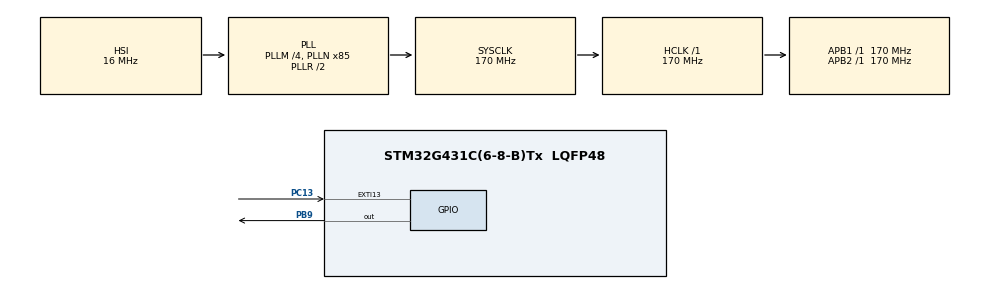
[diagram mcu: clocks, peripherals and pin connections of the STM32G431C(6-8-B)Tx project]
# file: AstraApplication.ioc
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Mcu.Family=STM32G4
Mcu.Name=STM32G431C(6-8-B)Tx
Mcu.Package=LQFP48
NVIC.EXTI15_10_IRQn=true\:0\:0\:false\:false\:true\:true\:true\:true
NVIC.PriorityGroup=NVIC_PRIORITYGROUP_4
PB9.Signal=GPIO_Output
PC13.GPIO_ModeDefaultEXTI=GPIO_MODE_IT_RISING
PC13.GPIO_PuPd=GPIO_PULLDOWN
PC13.Signal=GPXTI13
PC14-OSC32_IN.Mode=LSE-External-Oscillator
PC14-OSC32_IN.Signal=RCC_OSC32_IN
PC15-OSC32_OUT.Mode=LSE-External-Oscillator
PC15-OSC32_OUT.Signal=RCC_OSC32_OUT
PF0-OSC_IN.Mode=HSE-External-Oscillator
PF0-OSC_IN.Signal=RCC_OSC_IN
PF1-OSC_OUT.Mode=HSE-External-Oscillator
PF1-OSC_OUT.Signal=RCC_OSC_OUT
ProjectManager.HeapSize=0x200
ProjectManager.StackSize=0x400
ProjectManager.TargetToolchain=CMake
RCC.ADC12Freq_Value=170000000
RCC.AHBFreq_Value=170000000
RCC.APB1Freq_Value=170000000
RCC.APB1TimFreq_Value=170000000
RCC.APB2Freq_Value=170000000
RCC.APB2TimFreq_Value=170000000
RCC.CortexFreq_Value=170000000
RCC.EXTERNAL_CLOCK_VALUE=12288000
RCC.HCLKFreq_Value=170000000
RCC.HSE_VALUE=8000000
RCC.HSI48_VALUE=48000000
RCC.HSI_VALUE=16000000
RCC.PLLM=RCC_PLLM_DIV4
RCC.PLLN=85
RCC.SYSCLKFreq_VALUE=170000000
RCC.SYSCLKSource=RCC_SYSCLKSOURCE_PLLCLK
RCC.USBFreq_Value=170000000
RCC.VCOOutputFreq_Value=340000000
VP_SYS_VS_DBSignals.Mode=DisableDeadBatterySignals
board=custom

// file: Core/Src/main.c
/* USER CODE BEGIN Header */
/**
  ******************************************************************************
  * @file           : main.c
  * @brief          : Main program body
  ******************************************************************************
  * @attention
  *
  * Copyright (c) 2026 STMicroelectronics.
  * All rights reserved.
  *
  * This software is licensed under terms that can be found in the LICENSE file
  * in the root directory of this software component.
  * If no LICENSE file comes with this software, it is provided AS-IS.
  *
  ******************************************************************************
  */
/* USER CODE END Header */
#include "main.h"

/* USER CODE BEGIN Includes */
#include "FlashLayout.h"
#include "AppHeader.h"
#include "AstraFlash.h"
/* USER CODE END Includes */

/* USER CODE BEGIN PM */

uint32_t flash_buffer[PAGE_SIZE_WORDS];

void EnableOtaRequest(void)
{
    HAL_FLASH_Unlock();

    FlashReadPage(APP_HEADER_ADDR, flash_buffer);

    ((AppHeader_t *)flash_buffer)->otaRequest = OTA_REQUESTED;

    FlashErasePage(APP_HEADER_ADDR);

    FlashWritePage(APP_HEADER_ADDR, flash_buffer);

    HAL_FLASH_Lock();

    NVIC_SystemReset();
}
/* USER CODE END PM */

void SystemClock_Config(void);
static void MX_GPIO_Init(void);

int main(void)
{

  /* USER CODE BEGIN 1 */
  (void)GetAppHeader();
  /* USER CODE END 1 */

  /* MCU Configuration--------------------------------------------------------*/

  /* Reset of all peripherals, Initializes the Flash interface and the Systick. */
  HAL_Init();

  /* USER CODE BEGIN Init */
  SCB->VTOR = APP_START_ADDR;
	__enable_irq();
  /* USER CODE END Init */

  /* Configure the system clock */
  SystemClock_Config();

  /* Initialize all configured peripherals */
  MX_GPIO_Init();
  /* USER CODE BEGIN 2 */
  for (uint32_t blink = 0U; blink <= 3U; blink++)
  {
      HAL_GPIO_TogglePin(GPIOB, GPIO_PIN_9);
      HAL_Delay(500);
  }
  /* USER CODE END 2 */

  /* Infinite loop */
  while (1)
  {

  }
}

void SystemClock_Config(void)
{
  RCC_OscInitTypeDef RCC_OscInitStruct = {0};
  RCC_ClkInitTypeDef RCC_ClkInitStruct = {0};

  /** Configure the main internal regulator output voltage
  */
  HAL_PWREx_ControlVoltageScaling(PWR_REGULATOR_VOLTAGE_SCALE1_BOOST);

  /** Initializes the RCC Oscillators according to the specified parameters
  * in the RCC_OscInitTypeDef structure.
  */
  RCC_OscInitStruct.OscillatorType = RCC_OSCILLATORTYPE_HSI;
  RCC_OscInitStruct.HSIState = RCC_HSI_ON;
  RCC_OscInitStruct.HSICalibrationValue = RCC_HSICALIBRATION_DEFAULT;
  RCC_OscInitStruct.PLL.PLLState = RCC_PLL_ON;
  RCC_OscInitStruct.PLL.PLLSource = RCC_PLLSOURCE_HSI;
  RCC_OscInitStruct.PLL.PLLM = RCC_PLLM_DIV4;
  RCC_OscInitStruct.PLL.PLLN = 85;
  RCC_OscInitStruct.PLL.PLLP = RCC_PLLP_DIV2;
  RCC_OscInitStruct.PLL.PLLQ = RCC_PLLQ_DIV2;
  RCC_OscInitStruct.PLL.PLLR = RCC_PLLR_DIV2;
  if (HAL_RCC_OscConfig(&RCC_OscInitStruct) != HAL_OK)
  {
    Error_Handler();
  }

  /** Initializes the CPU, AHB and APB buses clocks
  */
  RCC_ClkInitStruct.ClockType = RCC_CLOCKTYPE_HCLK|RCC_CLOCKTYPE_SYSCLK
                              |RCC_CLOCKTYPE_PCLK1|RCC_CLOCKTYPE_PCLK2;
  RCC_ClkInitStruct.SYSCLKSource = RCC_SYSCLKSOURCE_PLLCLK;
  RCC_ClkInitStruct.AHBCLKDivider = RCC_SYSCLK_DIV1;
  RCC_ClkInitStruct.APB1CLKDivider = RCC_HCLK_DIV1;
  RCC_ClkInitStruct.APB2CLKDivider = RCC_HCLK_DIV1;

  if (HAL_RCC_ClockConfig(&RCC_ClkInitStruct, FLASH_LATENCY_4) != HAL_OK)
  {
    Error_Handler();
  }
}

static void MX_GPIO_Init(void)
{
  GPIO_InitTypeDef GPIO_InitStruct = {0};

  /* GPIO Ports Clock Enable */
  __HAL_RCC_GPIOC_CLK_ENABLE();
  __HAL_RCC_GPIOF_CLK_ENABLE();
  __HAL_RCC_GPIOB_CLK_ENABLE();

  /*Configure GPIO pin Output Level */
  HAL_GPIO_WritePin(GPIOB, GPIO_PIN_9, GPIO_PIN_RESET);

  /*Configure GPIO pin : PC13 */
  GPIO_InitStruct.Pin = GPIO_PIN_13;
  GPIO_InitStruct.Mode = GPIO_MODE_IT_RISING;
  GPIO_InitStruct.Pull = GPIO_PULLDOWN;
  HAL_GPIO_Init(GPIOC, &GPIO_InitStruct);

  /*Configure GPIO pin : PB9 */
  GPIO_InitStruct.Pin = GPIO_PIN_9;
  GPIO_InitStruct.Mode = GPIO_MODE_OUTPUT_PP;
  GPIO_InitStruct.Pull = GPIO_NOPULL;
  GPIO_InitStruct.Speed = GPIO_SPEED_FREQ_LOW;
  HAL_GPIO_Init(GPIOB, &GPIO_InitStruct);

  /* USER CODE BEGIN MX_GPIO_Init_2 */
  __HAL_GPIO_EXTI_CLEAR_IT(GPIO_PIN_13);
  /* USER CODE END MX_GPIO_Init_2 */

  /* EXTI interrupt init*/
  HAL_NVIC_SetPriority(EXTI15_10_IRQn, 0, 0);
  HAL_NVIC_EnableIRQ(EXTI15_10_IRQn);

}

/* USER CODE BEGIN 4 */
void HAL_GPIO_EXTI_Callback(uint16_t GPIO_Pin)
{
    uint32_t wait = 10000;
    while (wait--);

    EnableOtaRequest();
}
/* USER CODE END 4 */

void Error_Handler(void)
{
  __disable_irq();
  while (1)
  {
  }
}
